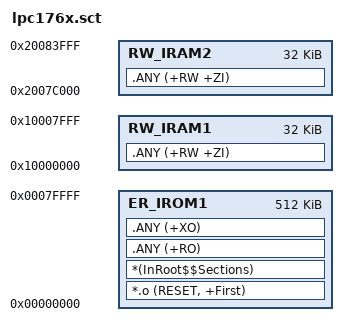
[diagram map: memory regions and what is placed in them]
;
; Scatter-loading descriptor for the LPC176x C
;
; *************************************************************
; *** Scatter-Loading Description File generated by uVision ***
; *************************************************************

LR_IROM1 0x00000000 0x00080000  
{
  ER_IROM1 0x00000000 0x00080000  
  {
   *.o (RESET, +First)
   *(InRoot$$Sections)
   .ANY (+RO)
   .ANY (+XO)
  }

  RW_IRAM1 0x10000000 0x00008000 
  {
   .ANY (+RW +ZI)
  }

  RW_IRAM2 0x2007C000 0x00008000
  {
   .ANY (+RW +ZI)
  }
}
